AUTOSAR XML (schema 3-2-1)
package /DoubleBlink/DoubleBlink_swc
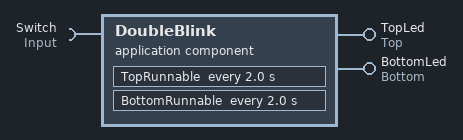
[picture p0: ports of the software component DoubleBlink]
  application software component type DoubleBlink
    require port Switch: unqueued-provider-com-spec{data-element=Toggle, alive-timeout=60.0}, provided-interface=Input
    provide port TopLed: unqueued-provider-com-spec{data-element=TopLed, alive-timeout=60.0}, provided-interface=Top
    provide port BottomLed: unqueued-provider-com-spec{data-element=BottomLed, alive-timeout=60.0}, provided-interface=Bottom
  internal behavior DoubleBlinkBehavior: component=DoubleBlink
    timing event TopEvent: start-on-event=TopRunnable, period=2.0
    timing event BottomEvent: start-on-event=BottomRunnable, period=2.0
    runnable TopRunnable: can-be-invoked-concurrently=true
      data read access InputAccess: data-element=Switch.Toggle
      data write access OutputAccess: data-element=TopLed.TopLed
    runnable BottomRunnable: can-be-invoked-concurrently=true
      data read access InputLedAccess: data-element=Switch.Toggle
      data write access BottomAccess: data-element=BottomLed.BottomLed
  swc implementation DoubleBlinkImplementation: behavior=DoubleBlinkBehavior
